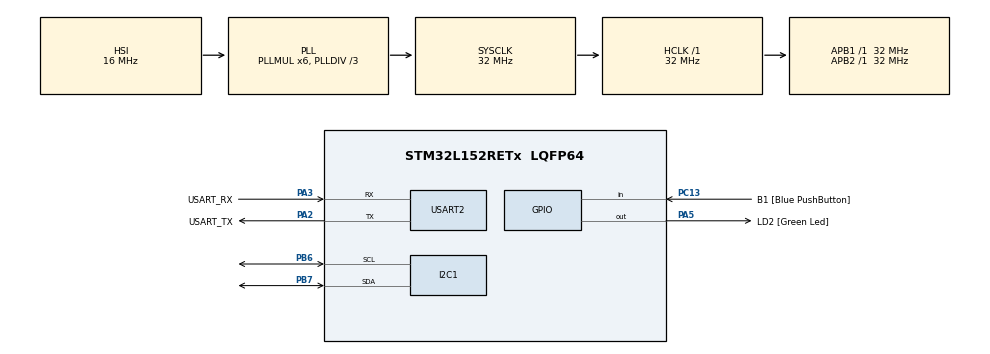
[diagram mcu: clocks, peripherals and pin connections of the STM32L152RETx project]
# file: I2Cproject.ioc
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Mcu.Family=STM32L1
Mcu.Name=STM32L152RETx
Mcu.Package=LQFP64
NVIC.PriorityGroup=NVIC_PRIORITYGROUP_0
PA13.GPIO_Label=TMS
PA13.Signal=SYS_JTMS-SWDIO
PA14.GPIO_Label=TCK
PA14.Signal=SYS_JTCK-SWCLK
PA2.GPIO_Label=USART_TX
PA2.Mode=Asynchronous
PA2.Signal=USART2_TX
PA3.GPIO_Label=USART_RX
PA3.Mode=Asynchronous
PA3.Signal=USART2_RX
PA5.GPIO_Label=LD2 [Green Led]
PA5.Signal=GPIO_Output
PB3.GPIO_Label=SWO
PB3.Signal=SYS_JTDO-TRACESWO
PB6.Mode=I2C
PB6.Signal=I2C1_SCL
PB7.Mode=I2C
PB7.Signal=I2C1_SDA
PC13-WKUP2.GPIO_Label=B1 [Blue PushButton]
PC13-WKUP2.Signal=GPIO_Input
PC14-OSC32_IN.Signal=RCC_OSC32_IN
PC15-OSC32_OUT.Signal=RCC_OSC32_OUT
PH0-OSC_IN.Signal=RCC_OSC_IN
PH1-OSC_OUT.Signal=RCC_OSC_OUT
ProjectManager.HeapSize=0x200
ProjectManager.StackSize=0x400
ProjectManager.TargetToolchain=EWARM
RCC.AHBFreq_Value=32000000
RCC.APB1Freq_Value=32000000
RCC.APB1TimFreq_Value=32000000
RCC.APB2Freq_Value=32000000
RCC.APB2TimFreq_Value=32000000
RCC.HCLKFreq_Value=32000000
RCC.HSE_VALUE=8000000
RCC.HSI_VALUE=16000000
RCC.LSE_VALUE=32768
RCC.MSI_VALUE=2097000
RCC.PLLDIV=RCC_PLL_DIV3
RCC.PLLMUL=RCC_PLL_MUL6
RCC.RTCClockSelectionVirtual=RCC_RTCCLKSOURCE_LSE
RCC.SYSCLKFreq_VALUE=32000000
RCC.SYSCLKSource=RCC_SYSCLKSOURCE_PLLCLK
RCC.USBOutput=48000000
RCC.VCOOutputFreq_Value=96000000
board=NUCLEO-L152RE

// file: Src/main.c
/**
  ******************************************************************************
  * File Name          : main.c
  * Description        : Main program body
  ******************************************************************************
  *
  * COPYRIGHT(c) 2017 STMicroelectronics
  *
  * Redistribution and use in source and binary forms, with or without modification,
  * are permitted provided that the following conditions are met:
  *   1. Redistributions of source code must retain the above copyright notice,
  *      this list of conditions and the following disclaimer.
  *   2. Redistributions in binary form must reproduce the above copyright notice,
  *      this list of conditions and the following disclaimer in the documentation
  *      and/or other materials provided with the distribution.
  *   3. Neither the name of STMicroelectronics nor the names of its contributors
  *      may be used to endorse or promote products derived from this software
  *      without specific prior written permission.
  *
  * THIS SOFTWARE IS PROVIDED BY THE COPYRIGHT HOLDERS AND CONTRIBUTORS "AS IS"
  * AND ANY EXPRESS OR IMPLIED WARRANTIES, INCLUDING, BUT NOT LIMITED TO, THE
  * IMPLIED WARRANTIES OF MERCHANTABILITY AND FITNESS FOR A PARTICULAR PURPOSE ARE
  * DISCLAIMED. IN NO EVENT SHALL THE COPYRIGHT HOLDER OR CONTRIBUTORS BE LIABLE
  * FOR ANY DIRECT, INDIRECT, INCIDENTAL, SPECIAL, EXEMPLARY, OR CONSEQUENTIAL
  * DAMAGES (INCLUDING, BUT NOT LIMITED TO, PROCUREMENT OF SUBSTITUTE GOODS OR
  * SERVICES; LOSS OF USE, DATA, OR PROFITS; OR BUSINESS INTERRUPTION) HOWEVER
  * CAUSED AND ON ANY THEORY OF LIABILITY, WHETHER IN CONTRACT, STRICT LIABILITY,
  * OR TORT (INCLUDING NEGLIGENCE OR OTHERWISE) ARISING IN ANY WAY OUT OF THE USE
  * OF THIS SOFTWARE, EVEN IF ADVISED OF THE POSSIBILITY OF SUCH DAMAGE.
  *
  ******************************************************************************
  */
#include "main.h"
#include "stm32l1xx_hal.h"

/* USER CODE BEGIN Includes */
#ifdef __GNUC__
/* With GCC/RAISONANCE, small printf (option LD Linker->Libraries->Small printf
   set to 'Yes') calls __io_putchar() */
#define PUTCHAR_PROTOTYPE int __io_putchar(int ch)
#else
#define PUTCHAR_PROTOTYPE int fputc(int ch, FILE *f)
#endif /* __GNUC__ */

/* USER CODE END Includes */

I2C_HandleTypeDef hi2c1;

UART_HandleTypeDef huart2;

/* USER CODE BEGIN PV */
/* Private variables ---------------------------------------------------------*/

/* USER CODE END PV */

void SystemClock_Config(void);
void Error_Handler(void);
uint8_t MPL3115A2_READ_REGISTER(uint8_t reg);
void MPL3115A2_WRITE_REGISTER(uint8_t reg, uint8_t value);
void MPL3115A2_Init();
void MPL3115A2_Activate();
int Pressure_Read_I2C();
double getBar();
void MPL3115A2_toggleOneShot();
static void MX_GPIO_Init(void);
static void MX_I2C1_Init(void);
static void MX_USART2_UART_Init(void);

/* USER CODE BEGIN PFP */
/* Private function prototypes -----------------------------------------------*/

/* USER CODE END PFP */

/* USER CODE BEGIN 0 */
uint8_t MPL3115A2_Initialized = 0;
/* USER CODE END 0 */

  int main(void)
{

  /* MCU Configuration----------------------------------------------------------*/

  /* Reset of all peripherals, Initializes the Flash interface and the Systick. */
  HAL_Init();

  /* Configure the system clock */
  SystemClock_Config();

  /* Initialize all configured peripherals */

  MX_GPIO_Init();
  MX_I2C1_Init();
  MX_USART2_UART_Init();

  /* USER CODE BEGIN 2 */
  MPL3115A2_Init();
  MPL3115A2_Activate();
  /* USER CODE END 2 */

  /* Infinite loop */
  /* USER CODE BEGIN WHILE */
  while (1)
  {

      double pressure = getBar();
      printf("Pressure : %.0f Pa\r \n", pressure);

      HAL_Delay(10);

  /* USER CODE END WHILE */

  }
}

/* MPL3115A2 INIT */
void MPL3115A2_Init(void)
{

  //INIT

    uint8_t c = MPL3115A2_READ_REGISTER(12);
	if (c == 0xc4)
	{
		MPL3115A2_Initialized = 1;
        MPL3115A2_WRITE_REGISTER(0x26, 0x38);
		MPL3115A2_WRITE_REGISTER(0x27, 0x00);
		MPL3115A2_WRITE_REGISTER(0x28, 0x11);
		MPL3115A2_WRITE_REGISTER(0x29, 0x00);
		MPL3115A2_WRITE_REGISTER(0x2a, 0x00);
		MPL3115A2_WRITE_REGISTER(0x13, 0x07);
	}
}

/* MPL3115A2 ACTIVATE */
void MPL3115A2_Activate(void)
{
  //ACTIVATE
        uint8_t v = MPL3115A2_READ_REGISTER(0x26);
        v = v | 0x01;
        MPL3115A2_WRITE_REGISTER(0x26,v);

}

int Pressure_Read_I2C(void)
{
  //READ
    int a=0;
    if (MPL3115A2_Initialized == 1) {

        uint8_t buf[3];
        int status = HAL_I2C_Mem_Read(&hi2c1, 0xc0, 1, I2C_MEMADD_SIZE_8BIT, buf, 3, HAL_MAX_DELAY);
        a = buf[0];
        a <<= 8;
        a = a + buf[1];
        a <<= 8;
        a = a + buf[2];
    }
    return a;
}

double getBar(void) {
	int v = Pressure_Read_I2C();
	int alt_m = v >> 6;
	int alt_l = v & 0x30;
	return alt_m + alt_l / 64.0;
}

int pressureReady(void) {
          uint8_t buf;
          uint8_t DR_STATUS = HAL_I2C_Mem_Read(&hi2c1, 0xc0, 06, I2C_MEMADD_SIZE_8BIT, &buf, 1, HAL_MAX_DELAY);
          if( (uint8_t)(buf  & 0x03) == 0x03)
          {
            return 1;
          }
          else
          {
            return 0;
          }

}

void MPL3115A2_toggleOneShot(void)
{
  uint8_t buf;
  uint8_t DR_STATUS = HAL_I2C_Mem_Read(&hi2c1, 0xc0, 06, I2C_MEMADD_SIZE_8BIT, &buf, 1, HAL_MAX_DELAY);
  buf = buf & 0xFB;
  MPL3115A2_WRITE_REGISTER(06,buf);
  buf = buf || 0x04;
  MPL3115A2_WRITE_REGISTER(06,buf);
}

/** System Clock Configuration
*/
void SystemClock_Config(void)
{

  RCC_OscInitTypeDef RCC_OscInitStruct;
  RCC_ClkInitTypeDef RCC_ClkInitStruct;

    /**Configure the main internal regulator output voltage
    */
  __HAL_PWR_VOLTAGESCALING_CONFIG(PWR_REGULATOR_VOLTAGE_SCALE1);

    /**Initializes the CPU, AHB and APB busses clocks
    */
  RCC_OscInitStruct.OscillatorType = RCC_OSCILLATORTYPE_HSI;
  RCC_OscInitStruct.HSIState = RCC_HSI_ON;
  RCC_OscInitStruct.HSICalibrationValue = 16;
  RCC_OscInitStruct.PLL.PLLState = RCC_PLL_ON;
  RCC_OscInitStruct.PLL.PLLSource = RCC_PLLSOURCE_HSI;
  RCC_OscInitStruct.PLL.PLLMUL = RCC_PLL_MUL6;
  RCC_OscInitStruct.PLL.PLLDIV = RCC_PLL_DIV3;
  if (HAL_RCC_OscConfig(&RCC_OscInitStruct) != HAL_OK)
  {
    Error_Handler();
  }

    /**Initializes the CPU, AHB and APB busses clocks
    */
  RCC_ClkInitStruct.ClockType = RCC_CLOCKTYPE_HCLK|RCC_CLOCKTYPE_SYSCLK
                              |RCC_CLOCKTYPE_PCLK1|RCC_CLOCKTYPE_PCLK2;
  RCC_ClkInitStruct.SYSCLKSource = RCC_SYSCLKSOURCE_PLLCLK;
  RCC_ClkInitStruct.AHBCLKDivider = RCC_SYSCLK_DIV1;
  RCC_ClkInitStruct.APB1CLKDivider = RCC_HCLK_DIV1;
  RCC_ClkInitStruct.APB2CLKDivider = RCC_HCLK_DIV1;

  if (HAL_RCC_ClockConfig(&RCC_ClkInitStruct, FLASH_LATENCY_1) != HAL_OK)
  {
    Error_Handler();
  }

    /**Configure the Systick interrupt time
    */
  HAL_SYSTICK_Config(HAL_RCC_GetHCLKFreq()/1000);

    /**Configure the Systick
    */
  HAL_SYSTICK_CLKSourceConfig(SYSTICK_CLKSOURCE_HCLK);

  /* SysTick_IRQn interrupt configuration */
  HAL_NVIC_SetPriority(SysTick_IRQn, 0, 0);
}

/* I2C1 init function */
static void MX_I2C1_Init(void)
{
	  GPIO_InitTypeDef GPIO_InitStruct;

	  /* Peripheral clock enable */
	  __HAL_RCC_I2C1_CLK_ENABLE();

	  hi2c1.Instance = I2C1;
	  hi2c1.Init.ClockSpeed = 100000;
	  hi2c1.Init.DutyCycle = I2C_DUTYCYCLE_2;
	  hi2c1.Init.OwnAddress1 = 0;
	  hi2c1.Init.AddressingMode = I2C_ADDRESSINGMODE_7BIT;
	  hi2c1.Init.DualAddressMode = I2C_DUALADDRESS_DISABLE;
	  hi2c1.Init.OwnAddress2 = 0;
	  hi2c1.Init.GeneralCallMode = I2C_GENERALCALL_DISABLE;
	  hi2c1.Init.NoStretchMode = I2C_NOSTRETCH_DISABLE;
	  //HAL_I2C_Init(&hi2c1);

	  GPIO_InitStruct.Pin =GPIO_PIN_6|GPIO_PIN_7;
	  GPIO_InitStruct.Mode = GPIO_MODE_AF_OD;
	  GPIO_InitStruct.Pull = GPIO_PULLUP;
	  GPIO_InitStruct.Speed = GPIO_SPEED_FREQ_VERY_HIGH;
	  GPIO_InitStruct.Alternate = GPIO_AF4_I2C1;
	  HAL_GPIO_Init(GPIOB, &GPIO_InitStruct);

  if (HAL_I2C_Init(&hi2c1) != HAL_OK)
  {
    Error_Handler();
  }
}

/* i2c reg read */
uint8_t MPL3115A2_READ_REGISTER(uint8_t reg)
{
	uint8_t buf;
        //HAL_I2C_Mem_Read(I2C_HandleTypeDef *hi2c, uint16_t DevAddress, uint16_t MemAddress, uint16_t MemAddSize, uint8_t *pData, uint16_t Size, uint32_t Timeout);
	int status = HAL_I2C_Mem_Read(&hi2c1, 0xc0, reg, I2C_MEMADD_SIZE_8BIT, &buf, 1, HAL_MAX_DELAY);
	return buf;
}

/* i2c reg write */
void MPL3115A2_WRITE_REGISTER(uint8_t reg, uint8_t value)
{

        //HAL_I2C_Mem_Write(I2C_HandleTypeDef *hi2c, uint16_t DevAddress, uint16_t MemAddress, uint16_t MemAddSize, uint8_t *pData, uint16_t Size, uint32_t Timeout);
         //HAL_I2C_Mem_Write(&hi2c1, 0xc0, reg, I2C_MEMADD_SIZE_8BIT, &value, strlen(value)+1, HAL_MAX_DELAY);

        uint8_t pData[]={reg, value };
        int status=HAL_I2C_Master_Transmit(&hi2c1, 0xc0, pData,2, HAL_MAX_DELAY);
}

/* USART2 init function */
static void MX_USART2_UART_Init(void)
{

  huart2.Instance = USART2;
  huart2.Init.BaudRate = 115200;
  huart2.Init.WordLength = UART_WORDLENGTH_8B;
  huart2.Init.StopBits = UART_STOPBITS_1;
  huart2.Init.Parity = UART_PARITY_NONE;
  huart2.Init.Mode = UART_MODE_TX_RX;
  huart2.Init.HwFlowCtl = UART_HWCONTROL_NONE;
  huart2.Init.OverSampling = UART_OVERSAMPLING_16;
  if (HAL_UART_Init(&huart2) != HAL_OK)
  {
    Error_Handler();
  }

}

/** Configure pins as
        * Analog
        * Input
        * Output
        * EVENT_OUT
        * EXTI
*/
static void MX_GPIO_Init(void)
{

  GPIO_InitTypeDef GPIO_InitStruct;

  /* GPIO Ports Clock Enable */
  __HAL_RCC_GPIOC_CLK_ENABLE();
  __HAL_RCC_GPIOH_CLK_ENABLE();
  __HAL_RCC_GPIOA_CLK_ENABLE();
  __HAL_RCC_GPIOB_CLK_ENABLE();

  /*Configure GPIO pin : B1_Pin */
  GPIO_InitStruct.Pin = B1_Pin;
  GPIO_InitStruct.Mode = GPIO_MODE_INPUT;
  GPIO_InitStruct.Pull = GPIO_NOPULL;
  HAL_GPIO_Init(B1_GPIO_Port, &GPIO_InitStruct);

  /*Configure GPIO pin : LD2_Pin */
  GPIO_InitStruct.Pin = LD2_Pin;
  GPIO_InitStruct.Mode = GPIO_MODE_OUTPUT_PP;
  GPIO_InitStruct.Pull = GPIO_NOPULL;
  GPIO_InitStruct.Speed = GPIO_SPEED_FREQ_LOW;
  HAL_GPIO_Init(LD2_GPIO_Port, &GPIO_InitStruct);

  /*Configure GPIO pin Output Level */
  HAL_GPIO_WritePin(LD2_GPIO_Port, LD2_Pin, GPIO_PIN_RESET);

}

void Error_Handler(void)
{
  while(1)
  {
  }
}

PUTCHAR_PROTOTYPE
{
  /* Place your implementation of fputc here */
  /* e.g. write a character to the USART3 and Loop until the end of transmission */
  HAL_UART_Transmit(&huart2, (uint8_t *)&ch, 1, 0xFFFF);

  return ch;
}

/************************ (C) COPYRIGHT STMicroelectronics *****END OF FILE****/
